# MIMXRT1021 register map
Vendor: nxp.com; File version: 1.0
CPU: CM7 r0p1, little endian, MPU, FPU, VTOR, 4 interrupt priority bits
Registers are 32-bit, read-write, reset 0x0 unless marked. A register's access mark holds for its fields unless they carry their own. Offsets are from the block's base; [hi:lo] are bit positions; 'fields as' and 'values as' point back to an identical list.

## SPDIF
Base 0x40380000; register names take the prefix SPDIF_
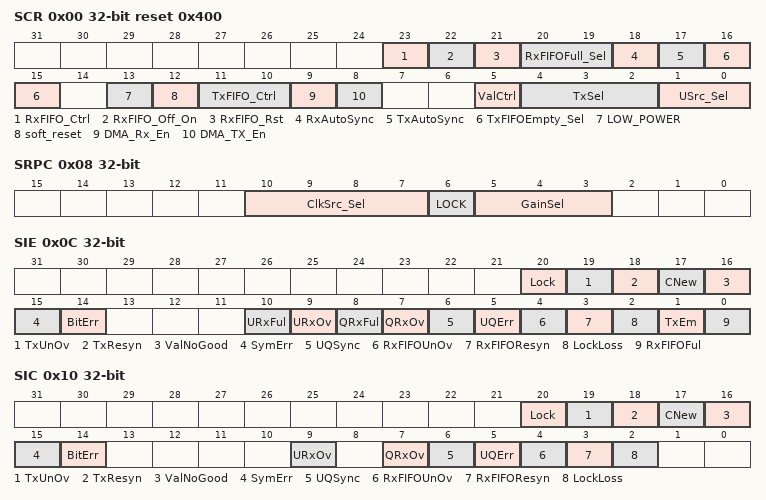
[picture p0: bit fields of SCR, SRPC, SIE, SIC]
0x00 SCR reset 0x400 — SPDIF Configuration Register
  [23] RxFIFO_Ctrl
    0=Normal operation; 1=Always read zero from Rx data register
  [22] RxFIFO_Off_On
    0=SPDIF Rx FIFO is on; 1=SPDIF Rx FIFO is off. Does not accept data from interface
  [21] RxFIFO_Rst
    0=Normal operation; 1=Reset register to 1 sample remaining
  [20:19] RxFIFOFull_Sel
    0=Full interrupt if at least 1 sample in Rx left and right FIFOs; 1=Full interrupt if at least 4 sample in Rx left and right FIFOs; 2=Full interrupt if at least 8 sample in Rx left and right FIFOs; 3=Full interrupt if at least 16 sample in Rx left and right FIFO
  [18] RxAutoSync
    0=Rx FIFO auto sync off; 1=RxFIFO auto sync on
  [17] TxAutoSync
    0=Tx FIFO auto sync off; 1=Tx FIFO auto sync on
  [16:15] TxFIFOEmpty_Sel
    0=Empty interrupt if 0 sample in Tx left and right FIFOs; 1=Empty interrupt if at most 4 sample in Tx left and right FIFOs; 2=Empty interrupt if at most 8 sample in Tx left and right FIFOs; 3=Empty interrupt if at most 12 sample in Tx left and right FIFOs
  [13] LOW_POWER — When write 1 to this bit, it will cause SPDIF enter low-power mode
  [12] soft_reset — When write 1 to this bit, it will cause SPDIF software reset
  [11:10] TxFIFO_Ctrl
    0=Send out digital zero on SPDIF Tx; 1=Tx Normal operation; 2=Reset to 1 sample remaining
  [9] DMA_Rx_En — DMA Receive Request Enable (RX FIFO full)
  [8] DMA_TX_En — DMA Transmit Request Enable (Tx FIFO empty)
  [5] ValCtrl
    0=Outgoing Validity always set; 1=Outgoing Validity always clear
  [4:2] TxSel
    0=Off and output 0; 1=Feed-through SPDIFIN; 5=Tx Normal operation
  [1:0] USrc_Sel
    0=No embedded U channel; 1=U channel from SPDIF receive block (CD mode); 3=U channel from on chip transmitter
0x04 SRCD — CDText Control Register
  [1] USyncMode
    0=Non-CD data; 1=CD user channel subcode
0x08 SRPC — PhaseConfig Register
  [10:7] ClkSrc_Sel — Clock source selection, all other settings not shown are reserved:
    0=if (DPLL Locked) SPDIF_RxClk else REF_CLK_32K (XTALOSC); 1=if (DPLL Locked) SPDIF_RxClk else tx_clk (SPDIF0_CLK_ROOT); 3=if (DPLL Locked) SPDIF_RxClk else SPDIF_EXT_CLK; 5=REF_CLK_32K (XTALOSC); 6=tx_clk (SPDIF0_CLK_ROOT); 8=SPDIF_EXT_CLK
  [6] LOCK ro — LOCK bit to show that the internal DPLL is locked, read only
  [5:3] GainSel — Gain selection:
    0=24*(2**10); 1=16*(2**10); 2=12*(2**10); 3=8*(2**10); 4=6*(2**10); 5=4*(2**10); 6=3*(2**10)
0x0C SIE — InterruptEn Register
  [20] Lock — SPDIF receiver's DPLL is locked
  [19] TxUnOv — SPDIF Tx FIFO under/overrun
  [18] TxResyn — SPDIF Tx FIFO resync
  [17] CNew — SPDIF receive change in value of control channel
  [16] ValNoGood — SPDIF validity flag no good
  [15] SymErr — SPDIF receiver found illegal symbol
  [14] BitErr — SPDIF receiver found parity bit error
  [10] URxFul — U Channel receive register full, can't be cleared with reg
  [9] URxOv — U Channel receive register overrun
  [8] QRxFul — Q Channel receive register full, can't be cleared with reg
  [7] QRxOv — Q Channel receive register overrun
  [6] UQSync — U/Q Channel sync found
  [5] UQErr — U/Q Channel framing error
  [4] RxFIFOUnOv — Rx FIFO underrun/overrun
  [3] RxFIFOResyn — Rx FIFO resync
  [2] LockLoss — SPDIF receiver loss of lock
  [1] TxEm — SPDIF Tx FIFO empty, can't be cleared with reg. IntClear. To clear it, write toTx FIFO.
  [0] RxFIFOFul — SPDIF Rx FIFO full, can't be cleared with reg. IntClear. To clear it, read from Rx FIFO.
0x10 SIC (SIC_SIS view) — InterruptClear Register
  [20] Lock wo — SPDIF receiver's DPLL is locked
  [19] TxUnOv wo — SPDIF Tx FIFO under/overrun
  [18] TxResyn wo — SPDIF Tx FIFO resync
  [17] CNew wo — SPDIF receive change in value of control channel
  [16] ValNoGood wo — SPDIF validity flag no good
  [15] SymErr wo — SPDIF receiver found illegal symbol
  [14] BitErr wo — SPDIF receiver found parity bit error
  [9] URxOv wo — U Channel receive register overrun
  [7] QRxOv wo — Q Channel receive register overrun
  [6] UQSync wo — U/Q Channel sync found
  [5] UQErr wo — U/Q Channel framing error
  [4] RxFIFOUnOv wo — Rx FIFO underrun/overrun
  [3] RxFIFOResyn wo — Rx FIFO resync
  [2] LockLoss wo — SPDIF receiver loss of lock
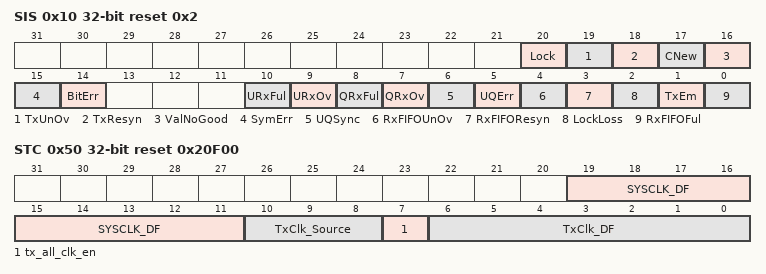
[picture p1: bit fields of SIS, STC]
0x10 SIS ro reset 0x2 (SIC_SIS view) — InterruptStat Register
  fields as SIE
0x14 SRL ro — SPDIFRxLeft Register
  [23:0] RxDataLeft — Processor receive SPDIF data left
0x18 SRR ro — SPDIFRxRight Register
  [23:0] RxDataRight — Processor receive SPDIF data right
0x1C SRCSH ro — SPDIFRxCChannel_h Register
  [23:0] RxCChannel_h — SPDIF receive C channel register, contains first 24 bits of C channel without interpretation
0x20 SRCSL ro — SPDIFRxCChannel_l Register
  [23:0] RxCChannel_l — SPDIF receive C channel register, contains next 24 bits of C channel without interpretation
0x24 SRU ro — UchannelRx Register
  [23:0] RxUChannel — SPDIF receive U channel register, contains next 3 U channel bytes
0x28 SRQ ro — QchannelRx Register
  [23:0] RxQChannel — SPDIF receive Q channel register, contains next 3 Q channel bytes
0x2C STL — SPDIFTxLeft Register
  [23:0] TxDataLeft wo — SPDIF transmit left channel data. It is write-only, and always returns zeros when read
0x30 STR — SPDIFTxRight Register
  [23:0] TxDataRight wo — SPDIF transmit right channel data. It is write-only, and always returns zeros when read
0x34 STCSCH — SPDIFTxCChannelCons_h Register
  [23:0] TxCChannelCons_h — SPDIF transmit Cons
0x38 STCSCL — SPDIFTxCChannelCons_l Register
  [23:0] TxCChannelCons_l — SPDIF transmit Cons
0x44 SRFM ro — FreqMeas Register
  [23:0] FreqMeas — Frequency measurement data
0x50 STC reset 0x20F00 — SPDIFTxClk Register
  [19:11] SYSCLK_DF — system clock divider factor, 2~512.
    0=no clock signal; 1=divider factor is 2; 0x1FF=divider factor is 512
  [10:8] TxClk_Source
    0=XTALOSC input (XTALOSC clock); 1=tx_clk input (from SPDIF0_CLK_ROOT. See CCM.); 2=tx_clk1 (from SAI1); 3=tx_clk2 SPDIF_EXT_CLK, from pads; 4=tx_clk3 (from SAI2); 5=ipg_clk input (frequency divided); 6=tx_clk4 (from SAI3)
  [7] tx_all_clk_en — Spdif transfer clock enable. When data is going to be transfered, this bit should be set to1.
    0=disable transfer clock; 1=enable transfer clock
  [6:0] TxClk_DF — Divider factor (1-128)
    0=divider factor is 1; 1=divider factor is 2; 127=divider factor is 128
